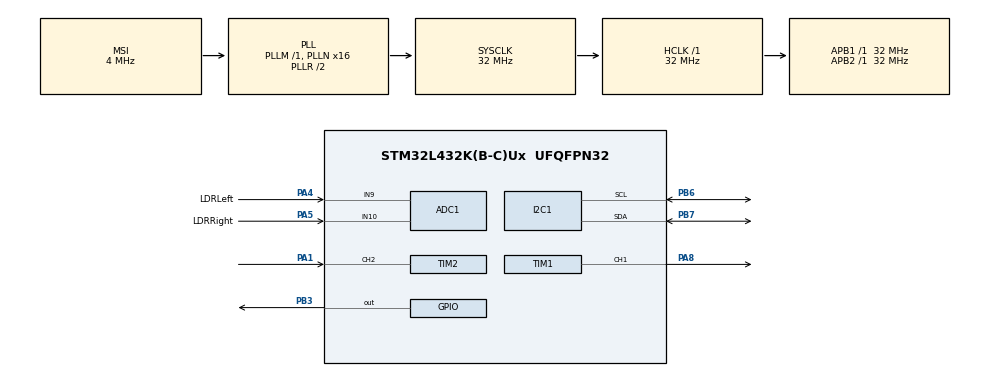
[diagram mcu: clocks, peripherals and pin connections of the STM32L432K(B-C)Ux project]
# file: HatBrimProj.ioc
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ADC1.Channel-0\#ChannelRegularConversion=ADC_CHANNEL_9
ADC1.Channel-1\#ChannelRegularConversion=ADC_CHANNEL_10
ADC1.NbrOfConversion=2
ADC1.NbrOfConversionFlag=1
ADC1.OffsetNumber-0\#ChannelRegularConversion=ADC_OFFSET_NONE
ADC1.OffsetNumber-1\#ChannelRegularConversion=ADC_OFFSET_NONE
ADC1.Rank-0\#ChannelRegularConversion=1
ADC1.Rank-1\#ChannelRegularConversion=2
ADC1.SamplingTime-0\#ChannelRegularConversion=ADC_SAMPLETIME_247CYCLES_5
ADC1.SamplingTime-1\#ChannelRegularConversion=ADC_SAMPLETIME_247CYCLES_5
ADC1.master=1
I2C1.Timing=0x00B07CB4
Mcu.Family=STM32L4
Mcu.Name=STM32L432K(B-C)Ux
Mcu.Package=UFQFPN32
NUCLEO-L432KC.Bsp_Common_DEMO=true
NUCLEO-L432KC.LD3=true
NVIC.PriorityGroup=NVIC_PRIORITYGROUP_4
NVIC.TIM2_IRQn=true\:0\:0\:false\:false\:true\:true\:true\:true
PA0.GPIO_Label=MCO [High speed clock in]
PA0.Signal=RCC_CK_IN
PA1.Signal=S_TIM2_CH2
PA13\ (JTMS-SWDIO).GPIO_Label=SWDIO
PA13\ (JTMS-SWDIO).Signal=SYS_JTMS-SWDIO
PA14\ (JTCK-SWCLK).GPIO_Label=SWCLK
PA14\ (JTCK-SWCLK).Signal=SYS_JTCK-SWCLK
PA15\ (JTDI).GPIO_Label=VCP_RX
PA15\ (JTDI).Signal=USART2_RX
PA2.GPIO_Label=VCP_TX
PA2.Signal=USART2_TX
PA4.GPIO_Label=LDRLeft
PA4.Signal=ADCx_IN9
PA5.GPIO_Label=LDRRight
PA5.Signal=ADCx_IN10
PA8.Signal=S_TIM1_CH1
PB3\ (JTDO-TRACESWO).Signal=GPIO_Output
PB6.Mode=I2C
PB6.Signal=I2C1_SCL
PB7.Mode=I2C
PB7.Signal=I2C1_SDA
PC14-OSC32_IN\ (PC14).Signal=RCC_OSC32_IN
PC15-OSC32_OUT\ (PC15).Signal=RCC_OSC32_OUT
ProjectManager.HeapSize=0x200
ProjectManager.StackSize=0x400
ProjectManager.TargetToolchain=STM32CubeIDE
RCC.ADCFreq_Value=32000000
RCC.AHBFreq_Value=32000000
RCC.APB1Freq_Value=32000000
RCC.APB1TimFreq_Value=32000000
RCC.APB2Freq_Value=32000000
RCC.APB2TimFreq_Value=32000000
RCC.CortexFreq_Value=32000000
RCC.HCLKFreq_Value=32000000
RCC.HSE_VALUE=8000000
RCC.HSI16_VALUE=16000000
RCC.HSI48_VALUE=48000000
RCC.HSI_VALUE=16000000
RCC.LSE_VALUE=32768
RCC.MSI_VALUE=4000000
RCC.PLLMUL=RCC_PLLMUL_4
RCC.PLLN=16
RCC.PLLSAI1N=16
RCC.SYSCLKFreq_VALUE=32000000
RCC.SYSCLKSource=RCC_SYSCLKSOURCE_PLLCLK
RCC.USBFreq_Value=32000000
RCC.VCOOutputFreq_Value=64000000
SH.ADCx_IN10.0=ADC1_IN10,IN10-Single-Ended
SH.ADCx_IN9.0=ADC1_IN9,IN9-Single-Ended
SH.S_TIM1_CH1.0=TIM1_CH1,PWM Generation1 CH1
SH.S_TIM2_CH2.0=TIM2_CH2,TriggerSource_TI2FP2
SH.S_TIM2_CH2.1=TIM2_CH2,Input_Capture2_from_TI2
TIM1.AutoReloadPreload=TIM_AUTORELOAD_PRELOAD_ENABLE
TIM1.Channel-PWM\ Generation1\ CH1=TIM_CHANNEL_1
TIM1.Period=19999
TIM1.Prescaler=31
TIM1.Pulse-PWM\ Generation1\ CH1=1500
TIM2.Channel-Input_Capture1_from_TI2_63=TIM_CHANNEL_1
TIM2.Channel-Input_Capture2_from_TI2=TIM_CHANNEL_2
TIM2.ICPolarity_CH1=TIM_INPUTCHANNELPOLARITY_FALLING
TIM2.Prescaler=3
VP_NUCLEO-L432KC_VS_BSP_COMMON.Mode=COMMON
VP_TIM1_VS_ClockSourceINT.Mode=Internal
VP_TIM2_VS_ClockSourceINT.Mode=Internal
VP_TIM2_VS_ControllerModeReset.Mode=Reset Mode
VP_TIM2_VS_indirect_ch2.Mode=Input_Capture1_from_TI2_63
board=NUCLEO-L432KC

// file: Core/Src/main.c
/* USER CODE BEGIN Header */
/**
 ******************************************************************************
 * @file           : main.c
 * @brief          : Main program body
 ******************************************************************************
 * @attention
 *
 * Copyright (c) 2026 STMicroelectronics.
 * All rights reserved.
 *
 * This software is licensed under terms that can be found in the LICENSE file
 * in the root directory of this software component.
 * If no LICENSE file comes with this software, it is provided AS-IS.
 *
 ******************************************************************************
 */
/* USER CODE END Header */
#include "main.h"
#include "adc.h"
#include "i2c.h"
#include "tim.h"
#include "gpio.h"

/* USER CODE BEGIN Includes */
/* --------------------------------------------- */
/* WHY: gives main.c the two bridge functions (app_init / app_loop) that are
   implemented in C++ in app.cpp. The old includes (bh1750.h, stdio.h,
   stdbool.h) moved to app.cpp together with the code that uses them. */
#include "app.h"
/* --------------------------------------------- */
/* USER CODE END Includes */

void SystemClock_Config(void);

int main(void) {

	/* MCU Configuration--------------------------------------------------------*/

	/* Reset of all peripherals, Initializes the Flash interface and the Systick. */
	HAL_Init();

	/* Configure the system clock */
	SystemClock_Config();

	/* Initialize all configured peripherals */
	MX_GPIO_Init();
	MX_TIM1_Init();
	MX_TIM2_Init();
	MX_I2C1_Init();
	MX_ADC1_Init();
	/* USER CODE BEGIN 2 */
	/* --------------------------------------------- */
	/* WHY: timer/ADC startup, calibration and the 180 ms delay used to be
	   written here. They now live in app_init() in app.cpp, so main.c only
	   needs this one call. */
	app_init();
	/* --------------------------------------------- */
	/* USER CODE END 2 */

	/* Initialize leds */
	BSP_LED_Init(LED_GREEN);

	/* USER CODE BEGIN BSP */

	/* -- Sample board code to switch on leds ---- */
	BSP_LED_On(LED_GREEN);

	/* USER CODE END BSP */

	/* Infinite loop */
	/* USER CODE BEGIN WHILE */
	while (1) {

		/* -- Sample board code to toggle leds -- */
		BSP_LED_Toggle(LED_GREEN);

		/* USER CODE END WHILE */

		/* USER CODE BEGIN 3 */
		// initially all my logic was in this main.c file. But i need to use C++ so i needed c++ files. now HAL and MX may overwrite this file if i change it to
		// c++. so i now call the main app as a loop. this was done using claude. see chat below.
		// https://claude.ai/share/4dc9b8e9-1304-4f1a-9f0f-5956f63ff31f
		/* --------------------------------------------- */
		/* WHY: the whole loop body (ADC read, moving average, servo logic,
		   100 ms delay) now lives in app_loop() in app.cpp. */
		app_loop();
		/* --------------------------------------------- */
	}
	/* USER CODE END 3 */
}

void SystemClock_Config(void) {
	RCC_OscInitTypeDef RCC_OscInitStruct = { 0 };
	RCC_ClkInitTypeDef RCC_ClkInitStruct = { 0 };

	/** Configure the main internal regulator output voltage
	 */
	if (HAL_PWREx_ControlVoltageScaling(PWR_REGULATOR_VOLTAGE_SCALE1)
			!= HAL_OK) {
		Error_Handler();
	}

	/** Initializes the RCC Oscillators according to the specified parameters
	 * in the RCC_OscInitTypeDef structure.
	 */
	RCC_OscInitStruct.OscillatorType = RCC_OSCILLATORTYPE_MSI;
	RCC_OscInitStruct.MSIState = RCC_MSI_ON;
	RCC_OscInitStruct.MSICalibrationValue = 0;
	RCC_OscInitStruct.MSIClockRange = RCC_MSIRANGE_6;
	RCC_OscInitStruct.PLL.PLLState = RCC_PLL_ON;
	RCC_OscInitStruct.PLL.PLLSource = RCC_PLLSOURCE_MSI;
	RCC_OscInitStruct.PLL.PLLM = 1;
	RCC_OscInitStruct.PLL.PLLN = 16;
	RCC_OscInitStruct.PLL.PLLP = RCC_PLLP_DIV7;
	RCC_OscInitStruct.PLL.PLLQ = RCC_PLLQ_DIV2;
	RCC_OscInitStruct.PLL.PLLR = RCC_PLLR_DIV2;
	if (HAL_RCC_OscConfig(&RCC_OscInitStruct) != HAL_OK) {
		Error_Handler();
	}

	/** Initializes the CPU, AHB and APB buses clocks
	 */
	RCC_ClkInitStruct.ClockType = RCC_CLOCKTYPE_HCLK | RCC_CLOCKTYPE_SYSCLK
			| RCC_CLOCKTYPE_PCLK1 | RCC_CLOCKTYPE_PCLK2;
	RCC_ClkInitStruct.SYSCLKSource = RCC_SYSCLKSOURCE_PLLCLK;
	RCC_ClkInitStruct.AHBCLKDivider = RCC_SYSCLK_DIV1;
	RCC_ClkInitStruct.APB1CLKDivider = RCC_HCLK_DIV1;
	RCC_ClkInitStruct.APB2CLKDivider = RCC_HCLK_DIV1;

	if (HAL_RCC_ClockConfig(&RCC_ClkInitStruct, FLASH_LATENCY_1) != HAL_OK) {
		Error_Handler();
	}
}

void Error_Handler(void) {
	__disable_irq();
	while (1) {
	}
}
